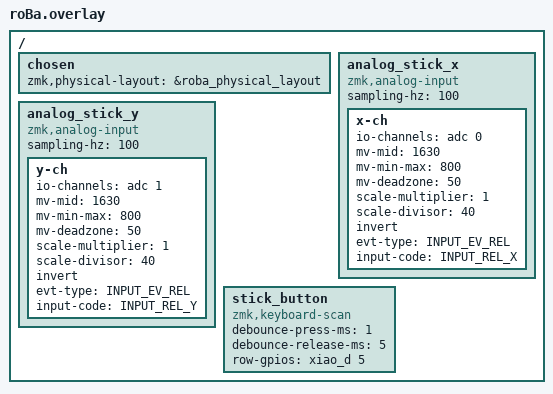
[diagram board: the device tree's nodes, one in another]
#include <zephyr/dt-bindings/input/input-event-codes.h>
#include <dt-bindings/zmk/matrix_transform.h>
#include <physical_layouts.dtsi>

/ {
    chosen {
        zmk,physical-layout = &roba_physical_layout;
    };
    
    analog_stick_x: analog_stick_x {
        compatible = "zmk,analog-input";
        sampling-hz = <100>;
        x-ch {
            io-channels = <&adc 0>;  // D1/A0
            mv-mid = <1630>;
            mv-min-max = <800>;
            mv-deadzone = <50>;
            scale-multiplier = <1>;
            scale-divisor = <40>;
            invert;
            evt-type = <INPUT_EV_REL>;
            input-code = <INPUT_REL_X>;
        };
    };

    analog_stick_y: analog_stick_y {
        compatible = "zmk,analog-input";
        sampling-hz = <100>;
        y-ch {
            io-channels = <&adc 1>;  // D2/A1
            mv-mid = <1630>;
            mv-min-max = <800>;
            mv-deadzone = <50>;
            scale-multiplier = <1>;
            scale-divisor = <40>;
            invert;
            evt-type = <INPUT_EV_REL>;
            input-code = <INPUT_REL_Y>;
        };
    };

    stick_button: stick_button {
        compatible = "zmk,keyboard-scan";
        debounce-press-ms = <1>;
        debounce-release-ms = <5>;
        row-gpios = <&xiao_d 5 (GPIO_ACTIVE_HIGH | GPIO_PULL_UP)>;
    };

    // ... existing code ...
} 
